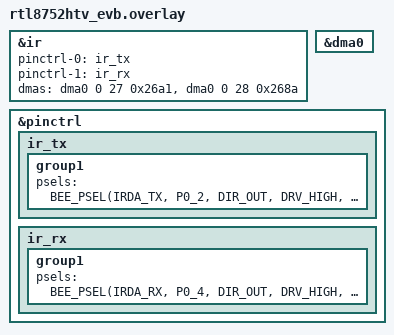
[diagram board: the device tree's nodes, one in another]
#include <dt-bindings/pinctrl/rtl8752h-pinctrl.h>

&ir {
	status = "okay";
	pinctrl-0 = <&ir_tx>;
	pinctrl-1 = <&ir_rx>;
	pinctrl-names = "ir-tx", "ir-rx";
	dmas = <&dma0 0 27 0x26a1>, <&dma0 0 28 0x268a>;
	dma-names = "tx", "rx";
};

&dma0 {
	status = "okay";
};

&pinctrl {
	ir_tx: ir_tx {
		group1 {
			psels = <BEE_PSEL(IRDA_TX, P0_2, DIR_OUT, DRV_HIGH, PULL_NONE)>;
		};
	};
	ir_rx: ir_rx {
		group1 {
			psels = <BEE_PSEL(IRDA_RX, P0_4, DIR_OUT, DRV_HIGH, PULL_NONE)>;
		};
	};
};
